# N32G033 register map
Vendor: Nsingtech Ltd.; File version: 1.0
Registers are 32-bit, read-write, reset 0x0 unless marked. A register's access mark holds for its fields unless they carry their own. Offsets are from the block's base; [hi:lo] are bit positions.

## I2C1
Base 0x40005400
Same registers: I2C2 0x40005800
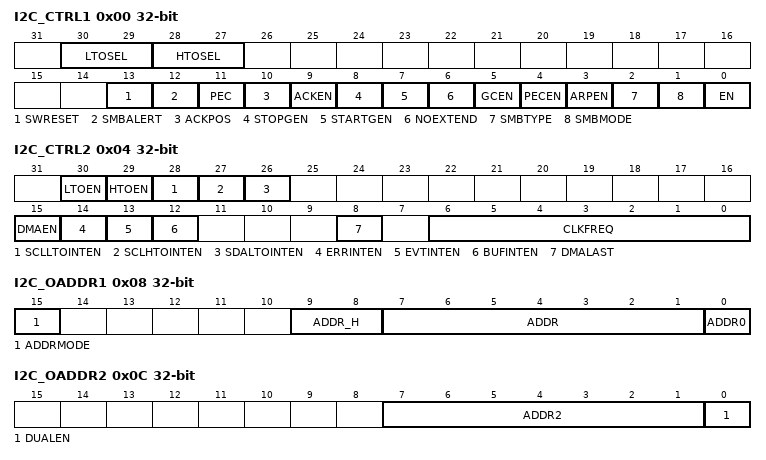
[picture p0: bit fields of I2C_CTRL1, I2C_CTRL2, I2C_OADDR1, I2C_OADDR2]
0x00 I2C_CTRL1 — nan
  [30:29] LTOSEL, [28:27] HTOSEL, [13] SWRESET, [12] SMBALERT, [11] PEC, [10] ACKPOS, [9] ACKEN, [8] STOPGEN, [7] STARTGEN, [6] NOEXTEND, [5] GCEN, [4] PECEN, [3] ARPEN, [2] SMBTYPE, [1] SMBMODE, [0] EN
0x04 I2C_CTRL2 — nan
  [30] LTOEN, [29] HTOEN, [28] SCLLTOINTEN, [27] SCLHTOINTEN, [26] SDALTOINTEN, [15] DMAEN, [14] ERRINTEN, [13] EVTINTEN, [12] BUFINTEN, [8] DMALAST, [6:0] CLKFREQ
0x08 I2C_OADDR1 — nan
  [15] ADDRMODE, [9:8] ADDR_H, [7:1] ADDR, [0] ADDR0
0x0C I2C_OADDR2 — nan
  [7:1] ADDR2, [0] DUALEN
0x10 I2C_DAT — nan
  [7:0] DAT
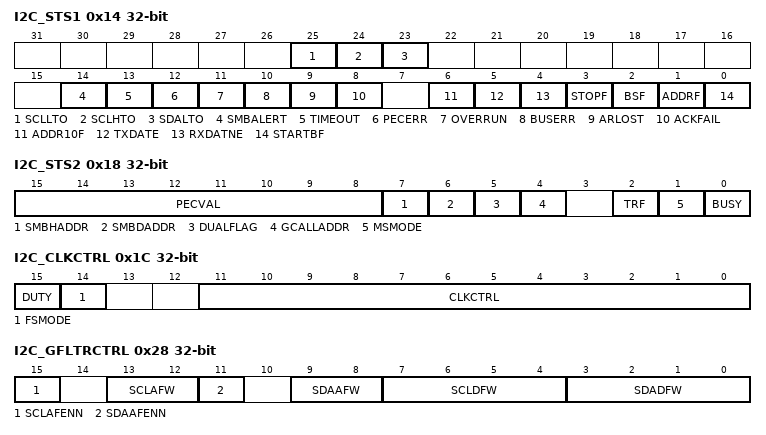
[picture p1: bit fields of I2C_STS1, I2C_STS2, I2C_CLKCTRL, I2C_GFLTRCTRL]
0x14 I2C_STS1 — nan
  [25] SCLLTO, [24] SCLHTO, [23] SDALTO, [14] SMBALERT, [13] TIMEOUT, [12] PECERR, [11] OVERRUN, [10] BUSERR, [9] ARLOST, [8] ACKFAIL, [6] ADDR10F, [5] TXDATE, [4] RXDATNE, [3] STOPF, [2] BSF, [1] ADDRF, [0] STARTBF
0x18 I2C_STS2 — nan
  [15:8] PECVAL, [7] SMBHADDR, [6] SMBDADDR, [5] DUALFLAG, [4] GCALLADDR, [2] TRF, [1] MSMODE, [0] BUSY
0x1C I2C_CLKCTRL — nan
  [15] DUTY, [14] FSMODE, [11:0] CLKCTRL
0x20 I2C_TMRISE reset 0x2 — nan
  [5:0] TMRISE
0x28 I2C_GFLTRCTRL — Filter control register
  [15] SCLAFENN, [13:12] SCLAFW, [11] SDAAFENN, [9:8] SDAAFW, [7:4] SCLDFW, [3:0] SDADFW

## IWDG
Base 0x40003000
0x00 IWDG_KEY — nan
  [15:0] KEYV
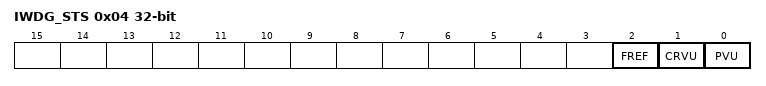
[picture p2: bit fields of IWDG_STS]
0x04 IWDG_STS — nan
  [2] FREF, [1] CRVU, [0] PVU
0x08 IWDG_PREDIV — nan
  [2:0] PD
0x0C IWDG_RELV reset 0xFFF — nan
  [13:0] REL
0x10 IWDG_CTRL — nan
  [0] ITE

## OPAMP
Base 0x40002000
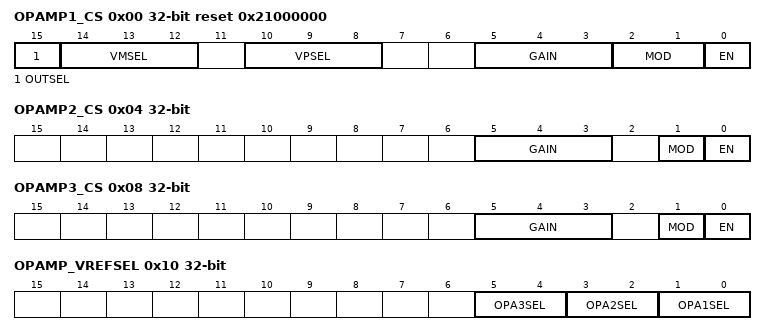
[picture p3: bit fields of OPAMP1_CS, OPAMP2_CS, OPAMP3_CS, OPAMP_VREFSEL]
0x00 OPAMP1_CS reset 0x21000000 — Opamp 1 control register
  [15] OUTSEL, [14:12] VMSEL, [10:8] VPSEL, [5:3] GAIN, [2:1] MOD, [0] EN
0x04 OPAMP2_CS — Opamp 2 control register
  [5:3] GAIN, [1] MOD, [0] EN
0x08 OPAMP3_CS — Opamp 3 control register
  [5:3] GAIN, [1] MOD, [0] EN
0x0C OPAMP_LOCK — Opamp123 lock register
  [0] OPALK
0x10 OPAMP_VREFSEL — Opamp1 reference voltage selection register
  [5:4] OPA3SEL, [3:2] OPA2SEL, [1:0] OPA1SEL

## PWR
Base 0x40007000
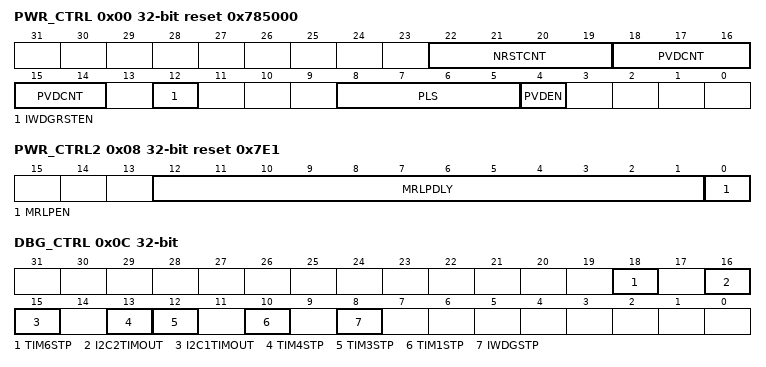
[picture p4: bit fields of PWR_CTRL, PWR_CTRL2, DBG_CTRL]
0x00 PWR_CTRL reset 0x785000 — Power Control Register
  [22:19] NRSTCNT, [18:14] PVDCNT, [12] IWDGRSTEN, [8:5] PLS, [4] PVDEN
0x04 PWR_CTRLSTS — Power Control/Status Register
  [2] PVDO
0x08 PWR_CTRL2 reset 0x7E1 — Power Control Register
  [12:1] MRLPDLY, [0] MRLPEN
0x0C DBG_CTRL — DBG MCU register.
  [18] TIM6STP, [16] I2C2TIMOUT, [15] I2C1TIMOUT, [13] TIM4STP, [12] TIM3STP, [10] TIM1STP, [8] IWDGSTP

## RCC
Base 0x40021000
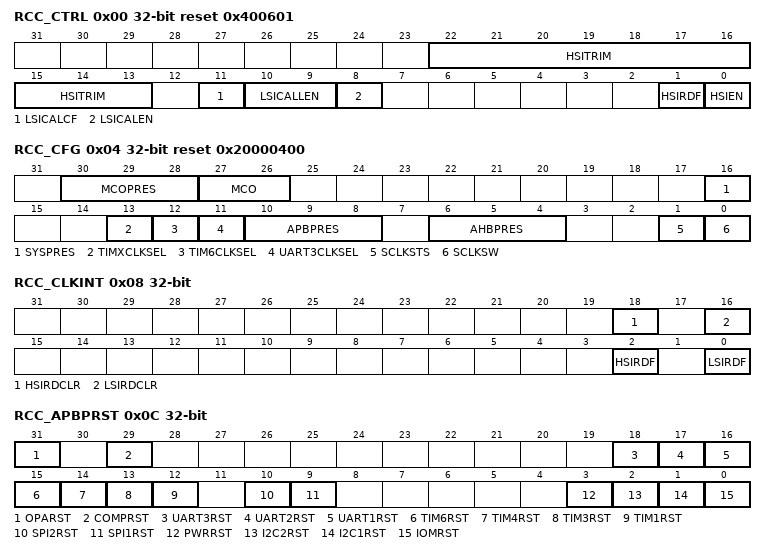
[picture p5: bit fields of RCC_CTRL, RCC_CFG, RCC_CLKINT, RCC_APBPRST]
0x00 RCC_CTRL reset 0x400601 — nan
  [22:13] HSITRIM, [11] LSICALCF, [10:9] LSICALLEN, [8] LSICALEN, [1] HSIRDF, [0] HSIEN
0x04 RCC_CFG reset 0x20000400 — nan
  [30:28] MCOPRES, [27:26] MCO, [16] SYSPRES, [13] TIMXCLKSEL, [12] TIM6CLKSEL, [11] UART3CLKSEL, [10:8] APBPRES, [6:4] AHBPRES, [1] SCLKSTS, [0] SCLKSW
0x08 RCC_CLKINT — nan
  [18] HSIRDCLR, [16] LSIRDCLR, [2] HSIRDF, [0] LSIRDF
0x0C RCC_APBPRST — nan
  [31] OPARST, [29] COMPRST, [18] UART3RST, [17] UART2RST, [16] UART1RST, [15] TIM6RST, [14] TIM4RST, [13] TIM3RST, [12] TIM1RST, [10] SPI2RST, [9] SPI1RST, [3] PWRRST, [2] I2C2RST, [1] I2C1RST, [0] IOMRST
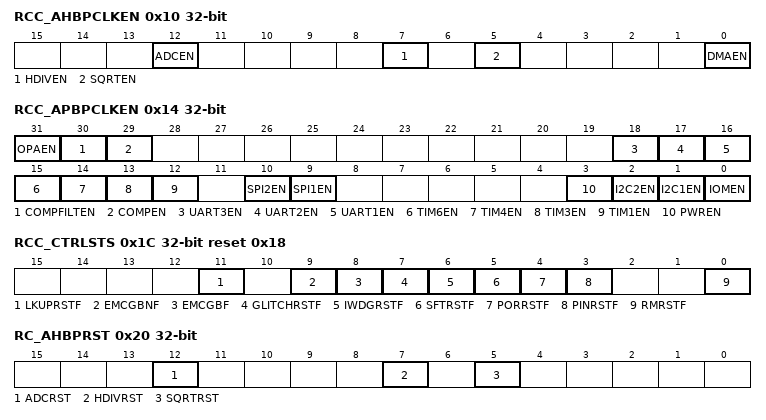
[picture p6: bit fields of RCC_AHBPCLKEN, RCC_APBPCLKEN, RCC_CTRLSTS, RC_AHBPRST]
0x10 RCC_AHBPCLKEN — nan
  [12] ADCEN, [7] HDIVEN, [5] SQRTEN, [0] DMAEN
0x14 RCC_APBPCLKEN — nan
  [31] OPAEN, [30] COMPFILTEN, [29] COMPEN, [18] UART3EN, [17] UART2EN, [16] UART1EN, [15] TIM6EN, [14] TIM4EN, [13] TIM3EN, [12] TIM1EN, [10] SPI2EN, [9] SPI1EN, [3] PWREN, [2] I2C2EN, [1] I2C1EN, [0] IOMEN
0x1C RCC_CTRLSTS reset 0x18 — nan
  [11] LKUPRSTF, [9] EMCGBNF, [8] EMCGBF, [7] GLITCHRSTF, [6] IWDGRSTF, [5] SFTRSTF, [4] PORRSTF, [3] PINRSTF, [0] RMRSTF
0x20 RC_AHBPRST — nan
  [12] ADCRST, [7] HDIVRST, [5] SQRTRST
0x24 RCC_CFG2 — nan
  [2:0] ADCHPRE
0x2C RCC_LSICAL — nan
  [23:0] HSICALCNT
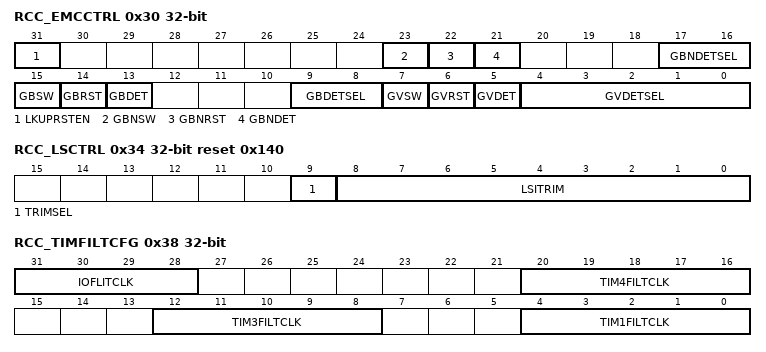
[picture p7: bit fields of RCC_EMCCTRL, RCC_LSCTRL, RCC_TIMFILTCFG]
0x30 RCC_EMCCTRL — nan
  [31] LKUPRSTEN, [23] GBNSW, [22] GBNRST, [21] GBNDET, [17:16] GBNDETSEL, [15] GBSW, [14] GBRST, [13] GBDET, [9:8] GBDETSEL, [7] GVSW, [6] GVRST, [5] GVDET, [4:0] GVDETSEL
0x34 RCC_LSCTRL reset 0x140 — nan
  [9] TRIMSEL, [8:0] LSITRIM
0x38 RCC_TIMFILTCFG — nan
  [31:28] IOFLITCLK, [20:16] TIM4FILTCLK, [12:8] TIM3FILTCLK, [4:0] TIM1FILTCLK
